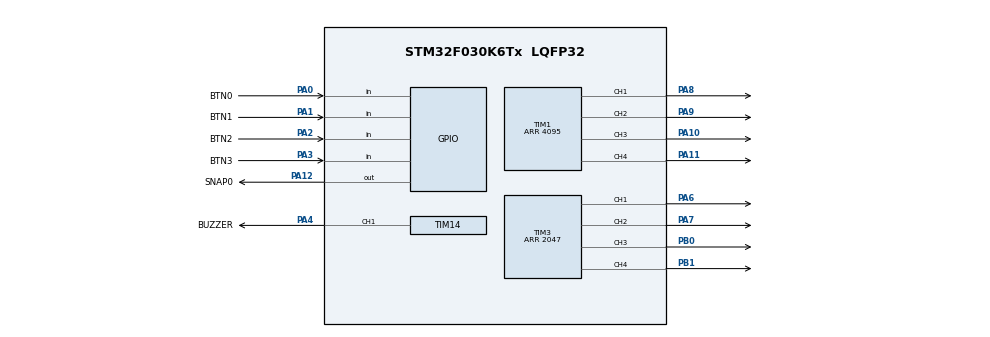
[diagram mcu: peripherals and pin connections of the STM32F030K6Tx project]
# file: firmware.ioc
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Dma.Request0=TIM1_CH3/UP
Dma.TIM1_CH3/UP.0.Direction=DMA_PERIPH_TO_MEMORY
Dma.TIM1_CH3/UP.0.Instance=DMA1_Channel5
Dma.TIM1_CH3/UP.0.MemDataAlignment=DMA_MDATAALIGN_HALFWORD
Dma.TIM1_CH3/UP.0.MemInc=DMA_MINC_ENABLE
Dma.TIM1_CH3/UP.0.Mode=DMA_CIRCULAR
Dma.TIM1_CH3/UP.0.PeriphDataAlignment=DMA_PDATAALIGN_HALFWORD
Dma.TIM1_CH3/UP.0.PeriphInc=DMA_PINC_DISABLE
Dma.TIM1_CH3/UP.0.Priority=DMA_PRIORITY_HIGH
Mcu.Family=STM32F0
Mcu.Name=STM32F030K6Tx
Mcu.Package=LQFP32
PA0.GPIO_Label=BTN0
PA0.GPIO_PuPd=GPIO_PULLUP
PA0.Signal=GPIO_Input
PA1.GPIO_Label=BTN1
PA1.GPIO_PuPd=GPIO_PULLUP
PA1.Signal=GPIO_Input
PA10.GPIO_Speed=GPIO_SPEED_FREQ_HIGH
PA10.Signal=S_TIM1_CH3
PA11.GPIO_Speed=GPIO_SPEED_FREQ_HIGH
PA11.Signal=S_TIM1_CH4
PA12.GPIO_Label=SNAP0
PA12.GPIO_Speed=GPIO_SPEED_FREQ_HIGH
PA12.PinState=GPIO_PIN_SET
PA12.Signal=GPIO_Output
PA13.Mode=Serial_Wire
PA13.Signal=SYS_SWDIO
PA14.Mode=Serial_Wire
PA14.Signal=SYS_SWCLK
PA2.GPIO_Label=BTN2
PA2.GPIO_PuPd=GPIO_PULLUP
PA2.Signal=GPIO_Input
PA3.GPIO_Label=BTN3
PA3.GPIO_PuPd=GPIO_PULLUP
PA3.Signal=GPIO_Input
PA4.GPIO_Label=BUZZER
PA4.GPIO_Speed=GPIO_SPEED_FREQ_HIGH
PA4.Signal=S_TIM14_CH1
PA6.GPIO_Speed=GPIO_SPEED_FREQ_HIGH
PA6.Signal=S_TIM3_CH1
PA7.GPIO_Speed=GPIO_SPEED_FREQ_HIGH
PA7.Signal=S_TIM3_CH2
PA8.GPIO_Speed=GPIO_SPEED_FREQ_HIGH
PA8.Signal=S_TIM1_CH1
PA9.GPIO_Speed=GPIO_SPEED_FREQ_HIGH
PA9.Signal=S_TIM1_CH2
PB0.GPIO_Speed=GPIO_SPEED_FREQ_HIGH
PB0.Signal=S_TIM3_CH3
PB1.GPIO_Speed=GPIO_SPEED_FREQ_HIGH
PB1.Signal=S_TIM3_CH4
ProjectManager.HeapSize=0x200
ProjectManager.StackSize=0x400
ProjectManager.TargetToolchain=MDK-ARM V5.27
RCC.AHBFreq_Value=48000000
RCC.APB1Freq_Value=48000000
RCC.APB1TimFreq_Value=48000000
RCC.HCLKFreq_Value=48000000
RCC.PLLMUL=RCC_PLL_MUL12
RCC.SYSCLKFreq_VALUE=48000000
RCC.SYSCLKSource=RCC_SYSCLKSOURCE_PLLCLK
SH.S_TIM14_CH1.0=TIM14_CH1,PWM Generation1 CH1
SH.S_TIM1_CH1.0=TIM1_CH1,PWM Generation1 CH1
SH.S_TIM1_CH2.0=TIM1_CH2,PWM Generation2 CH2
SH.S_TIM1_CH3.0=TIM1_CH3,PWM Generation3 CH3
SH.S_TIM1_CH4.0=TIM1_CH4,PWM Generation4 CH4
SH.S_TIM3_CH1.0=TIM3_CH1,PWM Generation1 CH1
SH.S_TIM3_CH2.0=TIM3_CH2,PWM Generation2 CH2
SH.S_TIM3_CH3.0=TIM3_CH3,PWM Generation3 CH3
SH.S_TIM3_CH4.0=TIM3_CH4,PWM Generation4 CH4
TIM1.Channel-PWM\ Generation1\ CH1=TIM_CHANNEL_1
TIM1.Channel-PWM\ Generation2\ CH2=TIM_CHANNEL_2
TIM1.Channel-PWM\ Generation3\ CH3=TIM_CHANNEL_3
TIM1.Channel-PWM\ Generation4\ CH4=TIM_CHANNEL_4
TIM1.OCIdleState_1=TIM_OCIDLESTATE_SET
TIM1.OCIdleState_2=TIM_OCIDLESTATE_SET
TIM1.OCIdleState_3=TIM_OCIDLESTATE_SET
TIM1.OCIdleState_4=TIM_OCIDLESTATE_SET
TIM1.OCMode_PWM-PWM\ Generation4\ CH4=TIM_OCMODE_PWM1
TIM1.OCPolarity_1=TIM_OCPOLARITY_LOW
TIM1.OCPolarity_2=TIM_OCPOLARITY_LOW
TIM1.OCPolarity_3=TIM_OCPOLARITY_HIGH
TIM1.OCPolarity_4=TIM_OCPOLARITY_HIGH
TIM1.Period=4095
TIM1.TIM_MasterOutputTrigger=TIM_TRGO_UPDATE
TIM1.TIM_MasterSlaveMode=TIM_MASTERSLAVEMODE_ENABLE
TIM14.AutoReloadPreload=TIM_AUTORELOAD_PRELOAD_ENABLE
TIM14.Channel=TIM_CHANNEL_1
TIM14.Period=30612
TIM14.Prescaler=43
TIM14.Pulse=15000
TIM3.Channel-PWM\ Generation1\ CH1=TIM_CHANNEL_1
TIM3.Channel-PWM\ Generation2\ CH2=TIM_CHANNEL_2
TIM3.Channel-PWM\ Generation3\ CH3=TIM_CHANNEL_3
TIM3.Channel-PWM\ Generation4\ CH4=TIM_CHANNEL_4
TIM3.CounterMode=TIM_COUNTERMODE_CENTERALIGNED3
TIM3.OC4Preload_PWM=DISABLE
TIM3.OCMode_PWM-PWM\ Generation1\ CH1=TIM_OCMODE_PWM2
TIM3.OCMode_PWM-PWM\ Generation2\ CH2=TIM_OCMODE_PWM2
TIM3.OCMode_PWM-PWM\ Generation3\ CH3=TIM_OCMODE_PWM2
TIM3.OCMode_PWM-PWM\ Generation4\ CH4=TIM_OCMODE_PWM2
TIM3.OCPolarity_1=TIM_OCPOLARITY_LOW
TIM3.OCPolarity_2=TIM_OCPOLARITY_LOW
TIM3.OCPolarity_3=TIM_OCPOLARITY_LOW
TIM3.OCPolarity_4=TIM_OCPOLARITY_LOW
TIM3.Period=2047
TIM3.Pulse-PWM\ Generation1\ CH1=20
TIM3.Pulse-PWM\ Generation2\ CH2=20
TIM3.Pulse-PWM\ Generation3\ CH3=20
TIM3.Pulse-PWM\ Generation4\ CH4=20
TIM3.TIM_MasterSlaveMode=TIM_MASTERSLAVEMODE_ENABLE
VP_TIM14_VS_ClockSourceINT.Mode=Enable_Timer
VP_TIM16_VS_ClockSourceINT.Mode=Enable_Timer
VP_TIM17_VS_ClockSourceINT.Mode=Enable_Timer
VP_TIM3_VS_ClockSourceITR.Mode=TriggerSource_ITR0
VP_TIM3_VS_ControllerModeReset.Mode=Reset Mode
board=custom

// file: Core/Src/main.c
/* USER CODE BEGIN Header */
/**
  ******************************************************************************
  * @file           : main.c
  * @brief          : Main program body
  ******************************************************************************
  * @attention
  *
  * <h2><center>&copy; Copyright (c) 2021 STMicroelectronics.
  * All rights reserved.</center></h2>
  *
  * This software component is licensed by ST under BSD 3-Clause license,
  * the "License"; You may not use this file except in compliance with the
  * License. You may obtain a copy of the License at:
  *                        opensource.org/licenses/BSD-3-Clause
  *
  ******************************************************************************
  */
/* USER CODE END Header */
#include "main.h"

void SystemClock_Config(void);
static void MX_GPIO_Init(void);
static void MX_DMA_Init(void);
static void MX_TIM14_Init(void);
static void MX_TIM16_Init(void);
static void MX_TIM17_Init(void);
static void MX_TIM1_Init(void);
static void MX_TIM3_Init(void);

int main(void)
{

  /* MCU Configuration--------------------------------------------------------*/

  /* Reset of all peripherals, Initializes the Flash interface and the Systick. */

  LL_APB1_GRP2_EnableClock(LL_APB1_GRP2_PERIPH_SYSCFG);
  LL_APB1_GRP1_EnableClock(LL_APB1_GRP1_PERIPH_PWR);

  /* System interrupt init*/

  /* Configure the system clock */
  SystemClock_Config();

  /* Initialize all configured peripherals */
  MX_GPIO_Init();
  MX_DMA_Init();
  MX_TIM14_Init();
  MX_TIM16_Init();
  MX_TIM17_Init();
  MX_TIM1_Init();
  MX_TIM3_Init();
  /* USER CODE BEGIN 2 */
    user_main();
  /* USER CODE END 2 */

  /* Infinite loop */
  while (1)
  {

  }
}

void SystemClock_Config(void)
{
  LL_FLASH_SetLatency(LL_FLASH_LATENCY_1);
  while(LL_FLASH_GetLatency() != LL_FLASH_LATENCY_1)
  {
  }
  LL_RCC_HSI_Enable();

   /* Wait till HSI is ready */
  while(LL_RCC_HSI_IsReady() != 1)
  {

  }
  LL_RCC_HSI_SetCalibTrimming(16);
  LL_RCC_PLL_ConfigDomain_SYS(LL_RCC_PLLSOURCE_HSI_DIV_2, LL_RCC_PLL_MUL_12);
  LL_RCC_PLL_Enable();

   /* Wait till PLL is ready */
  while(LL_RCC_PLL_IsReady() != 1)
  {

  }
  LL_RCC_SetAHBPrescaler(LL_RCC_SYSCLK_DIV_1);
  LL_RCC_SetAPB1Prescaler(LL_RCC_APB1_DIV_1);
  LL_RCC_SetSysClkSource(LL_RCC_SYS_CLKSOURCE_PLL);

   /* Wait till System clock is ready */
  while(LL_RCC_GetSysClkSource() != LL_RCC_SYS_CLKSOURCE_STATUS_PLL)
  {

  }
  LL_Init1msTick(48000000);
  LL_SetSystemCoreClock(48000000);
}

static void MX_TIM1_Init(void)
{

  LL_TIM_InitTypeDef TIM_InitStruct = {0};
  LL_TIM_OC_InitTypeDef TIM_OC_InitStruct = {0};
  LL_TIM_BDTR_InitTypeDef TIM_BDTRInitStruct = {0};

  LL_GPIO_InitTypeDef GPIO_InitStruct = {0};

  /* Peripheral clock enable */
  LL_APB1_GRP2_EnableClock(LL_APB1_GRP2_PERIPH_TIM1);

  /* TIM1 DMA Init */

  /* TIM1_CH3_UP Init */
  LL_DMA_SetDataTransferDirection(DMA1, LL_DMA_CHANNEL_5, LL_DMA_DIRECTION_PERIPH_TO_MEMORY);

  LL_DMA_SetChannelPriorityLevel(DMA1, LL_DMA_CHANNEL_5, LL_DMA_PRIORITY_HIGH);

  LL_DMA_SetMode(DMA1, LL_DMA_CHANNEL_5, LL_DMA_MODE_CIRCULAR);

  LL_DMA_SetPeriphIncMode(DMA1, LL_DMA_CHANNEL_5, LL_DMA_PERIPH_NOINCREMENT);

  LL_DMA_SetMemoryIncMode(DMA1, LL_DMA_CHANNEL_5, LL_DMA_MEMORY_INCREMENT);

  LL_DMA_SetPeriphSize(DMA1, LL_DMA_CHANNEL_5, LL_DMA_PDATAALIGN_HALFWORD);

  LL_DMA_SetMemorySize(DMA1, LL_DMA_CHANNEL_5, LL_DMA_MDATAALIGN_HALFWORD);

  TIM_InitStruct.Prescaler = 0;
  TIM_InitStruct.CounterMode = LL_TIM_COUNTERMODE_UP;
  TIM_InitStruct.Autoreload = 4095;
  TIM_InitStruct.ClockDivision = LL_TIM_CLOCKDIVISION_DIV1;
  TIM_InitStruct.RepetitionCounter = 0;
  LL_TIM_Init(TIM1, &TIM_InitStruct);
  LL_TIM_DisableARRPreload(TIM1);
  LL_TIM_OC_EnablePreload(TIM1, LL_TIM_CHANNEL_CH1);
  TIM_OC_InitStruct.OCMode = LL_TIM_OCMODE_PWM1;
  TIM_OC_InitStruct.OCState = LL_TIM_OCSTATE_DISABLE;
  TIM_OC_InitStruct.OCNState = LL_TIM_OCSTATE_DISABLE;
  TIM_OC_InitStruct.CompareValue = 0;
  TIM_OC_InitStruct.OCPolarity = LL_TIM_OCPOLARITY_LOW;
  TIM_OC_InitStruct.OCNPolarity = LL_TIM_OCPOLARITY_HIGH;
  TIM_OC_InitStruct.OCIdleState = LL_TIM_OCIDLESTATE_HIGH;
  TIM_OC_InitStruct.OCNIdleState = LL_TIM_OCIDLESTATE_LOW;
  LL_TIM_OC_Init(TIM1, LL_TIM_CHANNEL_CH1, &TIM_OC_InitStruct);
  LL_TIM_OC_DisableFast(TIM1, LL_TIM_CHANNEL_CH1);
  LL_TIM_OC_EnablePreload(TIM1, LL_TIM_CHANNEL_CH2);
  TIM_OC_InitStruct.OCState = LL_TIM_OCSTATE_DISABLE;
  TIM_OC_InitStruct.OCNState = LL_TIM_OCSTATE_DISABLE;
  LL_TIM_OC_Init(TIM1, LL_TIM_CHANNEL_CH2, &TIM_OC_InitStruct);
  LL_TIM_OC_DisableFast(TIM1, LL_TIM_CHANNEL_CH2);
  LL_TIM_OC_EnablePreload(TIM1, LL_TIM_CHANNEL_CH3);
  TIM_OC_InitStruct.OCState = LL_TIM_OCSTATE_DISABLE;
  TIM_OC_InitStruct.OCNState = LL_TIM_OCSTATE_DISABLE;
  TIM_OC_InitStruct.OCPolarity = LL_TIM_OCPOLARITY_HIGH;
  LL_TIM_OC_Init(TIM1, LL_TIM_CHANNEL_CH3, &TIM_OC_InitStruct);
  LL_TIM_OC_DisableFast(TIM1, LL_TIM_CHANNEL_CH3);
  LL_TIM_OC_EnablePreload(TIM1, LL_TIM_CHANNEL_CH4);
  TIM_OC_InitStruct.OCState = LL_TIM_OCSTATE_DISABLE;
  TIM_OC_InitStruct.OCNState = LL_TIM_OCSTATE_DISABLE;
  LL_TIM_OC_Init(TIM1, LL_TIM_CHANNEL_CH4, &TIM_OC_InitStruct);
  LL_TIM_OC_DisableFast(TIM1, LL_TIM_CHANNEL_CH4);
  LL_TIM_SetTriggerOutput(TIM1, LL_TIM_TRGO_UPDATE);
  LL_TIM_EnableMasterSlaveMode(TIM1);
  TIM_BDTRInitStruct.OSSRState = LL_TIM_OSSR_DISABLE;
  TIM_BDTRInitStruct.OSSIState = LL_TIM_OSSI_DISABLE;
  TIM_BDTRInitStruct.LockLevel = LL_TIM_LOCKLEVEL_OFF;
  TIM_BDTRInitStruct.DeadTime = 0;
  TIM_BDTRInitStruct.BreakState = LL_TIM_BREAK_DISABLE;
  TIM_BDTRInitStruct.BreakPolarity = LL_TIM_BREAK_POLARITY_HIGH;
  TIM_BDTRInitStruct.AutomaticOutput = LL_TIM_AUTOMATICOUTPUT_DISABLE;
  LL_TIM_BDTR_Init(TIM1, &TIM_BDTRInitStruct);
  LL_AHB1_GRP1_EnableClock(LL_AHB1_GRP1_PERIPH_GPIOA);
  /**TIM1 GPIO Configuration
  PA8   ------> TIM1_CH1
  PA9   ------> TIM1_CH2
  PA10   ------> TIM1_CH3
  PA11   ------> TIM1_CH4
  */
  GPIO_InitStruct.Pin = LL_GPIO_PIN_8;
  GPIO_InitStruct.Mode = LL_GPIO_MODE_ALTERNATE;
  GPIO_InitStruct.Speed = LL_GPIO_SPEED_FREQ_HIGH;
  GPIO_InitStruct.OutputType = LL_GPIO_OUTPUT_PUSHPULL;
  GPIO_InitStruct.Pull = LL_GPIO_PULL_NO;
  GPIO_InitStruct.Alternate = LL_GPIO_AF_2;
  LL_GPIO_Init(GPIOA, &GPIO_InitStruct);

  GPIO_InitStruct.Pin = LL_GPIO_PIN_9;
  GPIO_InitStruct.Mode = LL_GPIO_MODE_ALTERNATE;
  GPIO_InitStruct.Speed = LL_GPIO_SPEED_FREQ_HIGH;
  GPIO_InitStruct.OutputType = LL_GPIO_OUTPUT_PUSHPULL;
  GPIO_InitStruct.Pull = LL_GPIO_PULL_NO;
  GPIO_InitStruct.Alternate = LL_GPIO_AF_2;
  LL_GPIO_Init(GPIOA, &GPIO_InitStruct);

  GPIO_InitStruct.Pin = LL_GPIO_PIN_10;
  GPIO_InitStruct.Mode = LL_GPIO_MODE_ALTERNATE;
  GPIO_InitStruct.Speed = LL_GPIO_SPEED_FREQ_HIGH;
  GPIO_InitStruct.OutputType = LL_GPIO_OUTPUT_PUSHPULL;
  GPIO_InitStruct.Pull = LL_GPIO_PULL_NO;
  GPIO_InitStruct.Alternate = LL_GPIO_AF_2;
  LL_GPIO_Init(GPIOA, &GPIO_InitStruct);

  GPIO_InitStruct.Pin = LL_GPIO_PIN_11;
  GPIO_InitStruct.Mode = LL_GPIO_MODE_ALTERNATE;
  GPIO_InitStruct.Speed = LL_GPIO_SPEED_FREQ_HIGH;
  GPIO_InitStruct.OutputType = LL_GPIO_OUTPUT_PUSHPULL;
  GPIO_InitStruct.Pull = LL_GPIO_PULL_NO;
  GPIO_InitStruct.Alternate = LL_GPIO_AF_2;
  LL_GPIO_Init(GPIOA, &GPIO_InitStruct);

}

static void MX_TIM3_Init(void)
{

  LL_TIM_InitTypeDef TIM_InitStruct = {0};
  LL_TIM_OC_InitTypeDef TIM_OC_InitStruct = {0};

  LL_GPIO_InitTypeDef GPIO_InitStruct = {0};

  /* Peripheral clock enable */
  LL_APB1_GRP1_EnableClock(LL_APB1_GRP1_PERIPH_TIM3);

  TIM_InitStruct.Prescaler = 0;
  TIM_InitStruct.CounterMode = LL_TIM_COUNTERMODE_CENTER_UP_DOWN;
  TIM_InitStruct.Autoreload = 2047;
  TIM_InitStruct.ClockDivision = LL_TIM_CLOCKDIVISION_DIV1;
  LL_TIM_Init(TIM3, &TIM_InitStruct);
  LL_TIM_DisableARRPreload(TIM3);
  LL_TIM_OC_EnablePreload(TIM3, LL_TIM_CHANNEL_CH1);
  TIM_OC_InitStruct.OCMode = LL_TIM_OCMODE_PWM2;
  TIM_OC_InitStruct.OCState = LL_TIM_OCSTATE_DISABLE;
  TIM_OC_InitStruct.OCNState = LL_TIM_OCSTATE_DISABLE;
  TIM_OC_InitStruct.CompareValue = 20;
  TIM_OC_InitStruct.OCPolarity = LL_TIM_OCPOLARITY_LOW;
  LL_TIM_OC_Init(TIM3, LL_TIM_CHANNEL_CH1, &TIM_OC_InitStruct);
  LL_TIM_OC_DisableFast(TIM3, LL_TIM_CHANNEL_CH1);
  LL_TIM_OC_EnablePreload(TIM3, LL_TIM_CHANNEL_CH2);
  TIM_OC_InitStruct.OCState = LL_TIM_OCSTATE_DISABLE;
  TIM_OC_InitStruct.OCNState = LL_TIM_OCSTATE_DISABLE;
  LL_TIM_OC_Init(TIM3, LL_TIM_CHANNEL_CH2, &TIM_OC_InitStruct);
  LL_TIM_OC_DisableFast(TIM3, LL_TIM_CHANNEL_CH2);
  LL_TIM_OC_EnablePreload(TIM3, LL_TIM_CHANNEL_CH3);
  TIM_OC_InitStruct.OCState = LL_TIM_OCSTATE_DISABLE;
  TIM_OC_InitStruct.OCNState = LL_TIM_OCSTATE_DISABLE;
  LL_TIM_OC_Init(TIM3, LL_TIM_CHANNEL_CH3, &TIM_OC_InitStruct);
  LL_TIM_OC_DisableFast(TIM3, LL_TIM_CHANNEL_CH3);
  LL_TIM_OC_EnablePreload(TIM3, LL_TIM_CHANNEL_CH4);
  TIM_OC_InitStruct.OCState = LL_TIM_OCSTATE_DISABLE;
  TIM_OC_InitStruct.OCNState = LL_TIM_OCSTATE_DISABLE;
  LL_TIM_OC_Init(TIM3, LL_TIM_CHANNEL_CH4, &TIM_OC_InitStruct);
  LL_TIM_OC_DisableFast(TIM3, LL_TIM_CHANNEL_CH4);
  LL_TIM_SetTriggerInput(TIM3, LL_TIM_TS_ITR0);
  LL_TIM_SetSlaveMode(TIM3, LL_TIM_SLAVEMODE_RESET);
  LL_TIM_DisableIT_TRIG(TIM3);
  LL_TIM_DisableDMAReq_TRIG(TIM3);
  LL_TIM_SetTriggerOutput(TIM3, LL_TIM_TRGO_RESET);
  LL_TIM_EnableMasterSlaveMode(TIM3);
  LL_TIM_OC_DisablePreload(TIM3, LL_TIM_CHANNEL_CH4);
  LL_AHB1_GRP1_EnableClock(LL_AHB1_GRP1_PERIPH_GPIOA);
  LL_AHB1_GRP1_EnableClock(LL_AHB1_GRP1_PERIPH_GPIOB);
  /**TIM3 GPIO Configuration
  PA6   ------> TIM3_CH1
  PA7   ------> TIM3_CH2
  PB0   ------> TIM3_CH3
  PB1   ------> TIM3_CH4
  */
  GPIO_InitStruct.Pin = LL_GPIO_PIN_6;
  GPIO_InitStruct.Mode = LL_GPIO_MODE_ALTERNATE;
  GPIO_InitStruct.Speed = LL_GPIO_SPEED_FREQ_HIGH;
  GPIO_InitStruct.OutputType = LL_GPIO_OUTPUT_PUSHPULL;
  GPIO_InitStruct.Pull = LL_GPIO_PULL_NO;
  GPIO_InitStruct.Alternate = LL_GPIO_AF_1;
  LL_GPIO_Init(GPIOA, &GPIO_InitStruct);

  GPIO_InitStruct.Pin = LL_GPIO_PIN_7;
  GPIO_InitStruct.Mode = LL_GPIO_MODE_ALTERNATE;
  GPIO_InitStruct.Speed = LL_GPIO_SPEED_FREQ_HIGH;
  GPIO_InitStruct.OutputType = LL_GPIO_OUTPUT_PUSHPULL;
  GPIO_InitStruct.Pull = LL_GPIO_PULL_NO;
  GPIO_InitStruct.Alternate = LL_GPIO_AF_1;
  LL_GPIO_Init(GPIOA, &GPIO_InitStruct);

  GPIO_InitStruct.Pin = LL_GPIO_PIN_0;
  GPIO_InitStruct.Mode = LL_GPIO_MODE_ALTERNATE;
  GPIO_InitStruct.Speed = LL_GPIO_SPEED_FREQ_HIGH;
  GPIO_InitStruct.OutputType = LL_GPIO_OUTPUT_PUSHPULL;
  GPIO_InitStruct.Pull = LL_GPIO_PULL_NO;
  GPIO_InitStruct.Alternate = LL_GPIO_AF_1;
  LL_GPIO_Init(GPIOB, &GPIO_InitStruct);

  GPIO_InitStruct.Pin = LL_GPIO_PIN_1;
  GPIO_InitStruct.Mode = LL_GPIO_MODE_ALTERNATE;
  GPIO_InitStruct.Speed = LL_GPIO_SPEED_FREQ_HIGH;
  GPIO_InitStruct.OutputType = LL_GPIO_OUTPUT_PUSHPULL;
  GPIO_InitStruct.Pull = LL_GPIO_PULL_NO;
  GPIO_InitStruct.Alternate = LL_GPIO_AF_1;
  LL_GPIO_Init(GPIOB, &GPIO_InitStruct);

}

static void MX_TIM14_Init(void)
{

  LL_TIM_InitTypeDef TIM_InitStruct = {0};
  LL_TIM_OC_InitTypeDef TIM_OC_InitStruct = {0};

  LL_GPIO_InitTypeDef GPIO_InitStruct = {0};

  /* Peripheral clock enable */
  LL_APB1_GRP1_EnableClock(LL_APB1_GRP1_PERIPH_TIM14);

  TIM_InitStruct.Prescaler = 43;
  TIM_InitStruct.CounterMode = LL_TIM_COUNTERMODE_UP;
  TIM_InitStruct.Autoreload = 30612;
  TIM_InitStruct.ClockDivision = LL_TIM_CLOCKDIVISION_DIV1;
  LL_TIM_Init(TIM14, &TIM_InitStruct);
  LL_TIM_EnableARRPreload(TIM14);
  LL_TIM_OC_EnablePreload(TIM14, LL_TIM_CHANNEL_CH1);
  TIM_OC_InitStruct.OCMode = LL_TIM_OCMODE_PWM1;
  TIM_OC_InitStruct.OCState = LL_TIM_OCSTATE_DISABLE;
  TIM_OC_InitStruct.OCNState = LL_TIM_OCSTATE_DISABLE;
  TIM_OC_InitStruct.CompareValue = 15000;
  TIM_OC_InitStruct.OCPolarity = LL_TIM_OCPOLARITY_HIGH;
  LL_TIM_OC_Init(TIM14, LL_TIM_CHANNEL_CH1, &TIM_OC_InitStruct);
  LL_TIM_OC_DisableFast(TIM14, LL_TIM_CHANNEL_CH1);
  LL_AHB1_GRP1_EnableClock(LL_AHB1_GRP1_PERIPH_GPIOA);
  /**TIM14 GPIO Configuration
  PA4   ------> TIM14_CH1
  */
  GPIO_InitStruct.Pin = BUZZER_Pin;
  GPIO_InitStruct.Mode = LL_GPIO_MODE_ALTERNATE;
  GPIO_InitStruct.Speed = LL_GPIO_SPEED_FREQ_HIGH;
  GPIO_InitStruct.OutputType = LL_GPIO_OUTPUT_PUSHPULL;
  GPIO_InitStruct.Pull = LL_GPIO_PULL_NO;
  GPIO_InitStruct.Alternate = LL_GPIO_AF_4;
  LL_GPIO_Init(BUZZER_GPIO_Port, &GPIO_InitStruct);

}

static void MX_TIM16_Init(void)
{

  LL_TIM_InitTypeDef TIM_InitStruct = {0};

  /* Peripheral clock enable */
  LL_APB1_GRP2_EnableClock(LL_APB1_GRP2_PERIPH_TIM16);

  TIM_InitStruct.Prescaler = 0;
  TIM_InitStruct.CounterMode = LL_TIM_COUNTERMODE_UP;
  TIM_InitStruct.Autoreload = 65535;
  TIM_InitStruct.ClockDivision = LL_TIM_CLOCKDIVISION_DIV1;
  TIM_InitStruct.RepetitionCounter = 0;
  LL_TIM_Init(TIM16, &TIM_InitStruct);
  LL_TIM_DisableARRPreload(TIM16);

}

static void MX_TIM17_Init(void)
{

  LL_TIM_InitTypeDef TIM_InitStruct = {0};

  /* Peripheral clock enable */
  LL_APB1_GRP2_EnableClock(LL_APB1_GRP2_PERIPH_TIM17);

  TIM_InitStruct.Prescaler = 0;
  TIM_InitStruct.CounterMode = LL_TIM_COUNTERMODE_UP;
  TIM_InitStruct.Autoreload = 65535;
  TIM_InitStruct.ClockDivision = LL_TIM_CLOCKDIVISION_DIV1;
  TIM_InitStruct.RepetitionCounter = 0;
  LL_TIM_Init(TIM17, &TIM_InitStruct);
  LL_TIM_DisableARRPreload(TIM17);

}

static void MX_DMA_Init(void)
{

  /* Init with LL driver */
  /* DMA controller clock enable */
  LL_AHB1_GRP1_EnableClock(LL_AHB1_GRP1_PERIPH_DMA1);

  /* DMA interrupt init */
  /* DMA1_Channel4_5_IRQn interrupt configuration */
  NVIC_SetPriority(DMA1_Channel4_5_IRQn, 0);
  NVIC_EnableIRQ(DMA1_Channel4_5_IRQn);

}

static void MX_GPIO_Init(void)
{
  LL_GPIO_InitTypeDef GPIO_InitStruct = {0};

  /* GPIO Ports Clock Enable */
  LL_AHB1_GRP1_EnableClock(LL_AHB1_GRP1_PERIPH_GPIOA);
  LL_AHB1_GRP1_EnableClock(LL_AHB1_GRP1_PERIPH_GPIOB);

  /**/
  LL_GPIO_SetOutputPin(SNAP0_GPIO_Port, SNAP0_Pin);

  /**/
  GPIO_InitStruct.Pin = BTN0_Pin;
  GPIO_InitStruct.Mode = LL_GPIO_MODE_INPUT;
  GPIO_InitStruct.Pull = LL_GPIO_PULL_UP;
  LL_GPIO_Init(BTN0_GPIO_Port, &GPIO_InitStruct);

  /**/
  GPIO_InitStruct.Pin = BTN1_Pin;
  GPIO_InitStruct.Mode = LL_GPIO_MODE_INPUT;
  GPIO_InitStruct.Pull = LL_GPIO_PULL_UP;
  LL_GPIO_Init(BTN1_GPIO_Port, &GPIO_InitStruct);

  /**/
  GPIO_InitStruct.Pin = BTN2_Pin;
  GPIO_InitStruct.Mode = LL_GPIO_MODE_INPUT;
  GPIO_InitStruct.Pull = LL_GPIO_PULL_UP;
  LL_GPIO_Init(BTN2_GPIO_Port, &GPIO_InitStruct);

  /**/
  GPIO_InitStruct.Pin = BTN3_Pin;
  GPIO_InitStruct.Mode = LL_GPIO_MODE_INPUT;
  GPIO_InitStruct.Pull = LL_GPIO_PULL_UP;
  LL_GPIO_Init(BTN3_GPIO_Port, &GPIO_InitStruct);

  /**/
  GPIO_InitStruct.Pin = SNAP0_Pin;
  GPIO_InitStruct.Mode = LL_GPIO_MODE_OUTPUT;
  GPIO_InitStruct.Speed = LL_GPIO_SPEED_FREQ_HIGH;
  GPIO_InitStruct.OutputType = LL_GPIO_OUTPUT_PUSHPULL;
  GPIO_InitStruct.Pull = LL_GPIO_PULL_NO;
  LL_GPIO_Init(SNAP0_GPIO_Port, &GPIO_InitStruct);

}

void Error_Handler(void)
{
}

/************************ (C) COPYRIGHT STMicroelectronics *****END OF FILE****/
